# nrf9120_mlm1_modem register map
Vendor: Nordic Semiconductor; Series: nrf91; File version: 1
CPU: CM4 r0p1, little endian, MPU, no FPU, 3 interrupt priority bits
Registers are 32-bit, read-write, reset 0x0 unless marked. A register's access mark holds for its fields unless they carry their own. Offsets are from the block's base; [hi:lo] are bit positions; lines under a group give offsets from that group; {n}, {i} and the like mark numbered series; 'fields as' and 'values as' point back to an identical list.

## UICR — User Information Configuration Registers
Base 0x00FF8000
{0x0+4i} NCKLOCK[{i}] (i=0..3) ro reset 0xFFFFFFFF — Description collection: Encrypted unlock code data for network lock n
  [31:0] NCKLOCK — Encrypted unlock code data, word n
{0x10+4i} NSCKLOCK[{i}] (i=0..3) ro reset 0xFFFFFFFF — Description collection: Encrypted unlock code data for network subset lock n
  [31:0] NSCKLOCK — Encrypted unlock code data, word n
{0x20+4i} SPCKLOCK[{i}] (i=0..3) ro reset 0xFFFFFFFF — Description collection: Encrypted unlock code data for service provider lock n
  [31:0] SPCKLOCK — Encrypted unlock code data, word n
{0x30+4i} CCKLOCK[{i}] (i=0..3) ro reset 0xFFFFFFFF — Description collection: Encrypted unlock code data for corporate lock n
  [31:0] CCKLOCK — Encrypted unlock code data, word n
{0x40+4i} PCKLOCK[{i}] (i=0..3) ro reset 0xFFFFFFFF — Description collection: Encrypted unlock code data for SIM/USIM lock n
  [31:0] PCKLOCK — Encrypted unlock code data, word n
{0x50+4i} MASTERLOCK[{i}] (i=0..3) ro reset 0xFFFFFFFF — Description collection: Space reservation for encrypted master unlock code data n
  [31:0] MASTERLOCK — Encrypted unlock code data, word n
{0x60+4i} PROVIS[{i}] (i=0..3) ro reset 0xFFFFFFFF — Description collection: Provisioning data n
  [31:0] PROVIS — Customer provisioning data, word n
{0x70+4i} CUSTIMEI[{i}] (i=0..1) ro reset 0xFFFFFFFF — Description collection: Customer IMEI n, used if FICR->IMEI is not programmed
  [31:0] CIMEI — Customer IMEI in BCD decoded nibbles
{0x80+4i} CUSTMAC0[{i}] (i=0..1) ro reset 0xFFFFFFFF — Description collection: Customer MAC0 n, used if FICR->MAC0 is not programmed
  [31:0] CUSTMAC0 — Customer MAC0 value
{0x88+4i} CUSTMAC1[{i}] (i=0..1) ro reset 0xFFFFFFFF — Description collection: Customer MAC1 n, used if FICR->MAC1 is not programmed
  [31:0] CUSTMAC1 — Customer MAC1 value
{0x90+4i} CUSTMAC2[{i}] (i=0..1) ro reset 0xFFFFFFFF — Description collection: Customer MAC2 n, used if FICR->MAC2 is not programmed
  [31:0] CUSTMAC2 — Customer MAC2 value
{0x98+4i} CUSTMAC3[{i}] (i=0..1) ro reset 0xFFFFFFFF — Description collection: Customer MAC3 n, used if FICR->MAC3 is not programmed
  [31:0] CUSTMAC3 — Customer MAC3 value
{0xA0+4i} CUSTDEVCONF[{i}] (i=0..3) ro reset 0xFFFFFFFF — Description collection: Customer device configuration n, may be used to further limit configuration done by FICR->DEVCONF
  [31:0] CUSTDEVCONF — Customer device configuration data word n, contents defined in SW
0x800 SIMLOCK ro reset 0xFFFFFFFF — SIM lock data. Content and length T.B.D.
0xE00 RFTUNING ro reset 0xFFFFFFFF — RF tuning data. Content and length T.B.D.

## AMLI — AHB Multi-Layer Interface
Base 0x40000000
0xE00 RAMPRI group — RAM configurable priority configuration structure
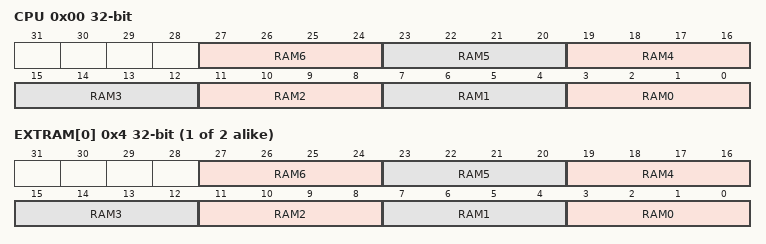
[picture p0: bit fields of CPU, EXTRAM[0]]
  0x00 CPU — AHB bus master priority register for CPU
    [all] fields
      {v}=Pri{v} (Priority {v}) (v=0..15)
    [4n+3:4n] RAM{n} (n=0..6) — Priority register for RAM AHB slave {n}
  {0x4+4j} EXTRAM[{j}] (j=0..1) — Description collection: AHB bus master priority register for external RAM slave port (EXTRAMs)
    fields as RAMPRI.CPU

## DCNF — Domain Configuration Management
Base 0x40000000; alternate view of AMLI
0x420 CPUID ro reset 0x1 — CPU number in the system
  [7:0] CPUID
0x440 EXTPERI0 group — Unspecified
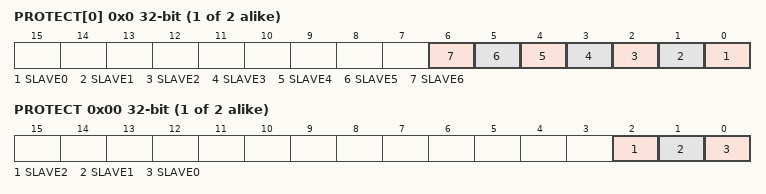
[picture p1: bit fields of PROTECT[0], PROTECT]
  {0x0+4j} PROTECT[{j}] (j=0..1) — Description collection: Control access for Master connected to AMLI master port EXTPERI[n]
    [all] fields
      0=Allowed (Access to slave is possible); 1=Blocked (Access to slave is blocked)
    [n] SLAVE{n} (n=0..6) — Control access to slave {n} of master EXTPERI[n].
0x460 EXTRAM group — Unspecified
  {0x0+4j} PROTECT[{j}] (j=0..1) — Description collection: Control access from Master connected to AMLI master port EXTRAM[n]
    [all] fields
      values as the fields of EXTPERI0.PROTECT[0]
    [n] SLAVE{n} (n=0..7) — Control access to slave {n} of master EXTRAM[n].
{0x480+4i} EXTCODE[{i}] (i=0..1) group — Unspecified
  0x00 PROTECT — Description cluster: Control access from Master connected to AMLI master port EXTCODE[n]
    [all] fields
      values as the fields of EXTPERI0.PROTECT[0]
    [2] SLAVE2 — Control access to slave 2 of master EXTCODE[n].
    [1] SLAVE1 — Control access to slave 1 of master EXTCODE[n].
    [0] SLAVE0 — Control access to slave 0 of master EXTCODE[n].
